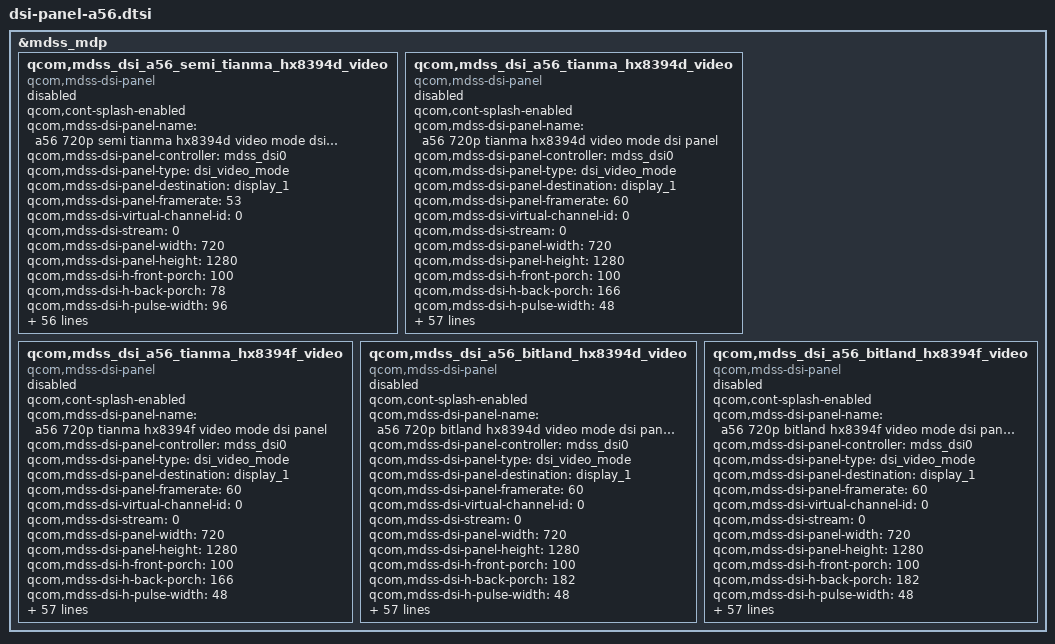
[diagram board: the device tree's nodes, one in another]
&mdss_mdp {
	qcom,mdss_dsi_a56_semi_tianma_hx8394d_video {
		compatible = "qcom,mdss-dsi-panel";
		status = "disable";
		qcom,cont-splash-enabled;
		qcom,mdss-dsi-panel-name = "a56 720p semi tianma hx8394d video mode dsi panel";
		qcom,mdss-dsi-panel-controller = <&mdss_dsi0>;
		qcom,mdss-dsi-panel-type = "dsi_video_mode";
		qcom,mdss-dsi-panel-destination = "display_1";
		qcom,mdss-dsi-panel-framerate = <53>;
		qcom,mdss-dsi-virtual-channel-id = <0>;
		qcom,mdss-dsi-stream = <0>;
		qcom,mdss-dsi-panel-width = <720>;
		qcom,mdss-dsi-panel-height = <1280>;
		qcom,mdss-dsi-h-front-porch = <100>;
		qcom,mdss-dsi-h-back-porch = <78>;
		qcom,mdss-dsi-h-pulse-width = <96>;
		qcom,mdss-dsi-h-sync-skew = <0>;
		qcom,mdss-dsi-v-back-porch = <16>;
		qcom,mdss-dsi-v-front-porch = <9>;
		qcom,mdss-dsi-v-pulse-width = <2>;
		qcom,mdss-dsi-h-left-border = <0>;
		qcom,mdss-dsi-h-right-border = <0>;
		qcom,mdss-dsi-v-top-border = <0>;
		qcom,mdss-dsi-v-bottom-border = <0>;
		qcom,mdss-dsi-bpp = <24>;
		qcom,mdss-dsi-color-order = "rgb_swap_rgb";
		qcom,mdss-dsi-underflow-color = <0xff>;
		qcom,mdss-dsi-border-color = <0>;
		qcom,mdss-dsi-on-command = [
			 39 01 00 00 00 00 04 B9 FF 83 94 /* Set EXTC */
			 39 01 00 00 00 00 03 BA 72 83 /* Set MIPI: 0x72=3Lane, 0x73=4lane */
			 39 01 00 00 00 00 10 B1 6C 0F 0F 35 04 11 F1 80 DE D4 23 80 C0 D2 18 /* Set Power */
			 39 01 00 00 00 00 0C B2 00 64 0E 0D 32 23 08 08 1C 4D 00 /* Set Display: column inversion */
			 15 01 00 00 00 00 02 BC 07 /* set VDDD: 1.7V */
			 39 01 00 00 00 00 0D B4 00 FF 03 5A 03 5A 03 5A 01 6A 01 6A  /* Set CYC(panel driving timing): column inversion */
			 39 01 00 00 00 00 26 D3 00 07 00 00 00 10 00 32 10 05 00 05 32 10 00 00 00 32 10 00 00 00 36 03 09 09 37 00 00 37 00 00 00 00 0A 00 01 /* Set GIP option 0: column inversion */
			 39 01 00 00 00 00 2D D5 02 03 00 01 06 07 04 05 20 21 22 23 18 18 18 18 18 18 18 18 18 18 18 18 18 18 18 18 18 18 18 18 18 18 18 18 18 18 24 25 18 18 19 19 /* Set GIP option 1 */
			 39 01 00 00 00 00 2D D6 05 04 07 06 01 00 03 02 23 22 21 20 18 18 18 18 18 18 18 18 18 18 18 18 18 18 18 18 18 18 18 18 18 18 18 18 18 18 25 24 19 19 18 18 /* Set GIP option 2 */
			 39 01 00 00 00 00 2B E0 00 11 16 2F 35 3F 25 3E 08 0B 0D 17 0E 12 14 13 14 07 10 11 18 00 10 17 30 35 3F 24 3E 07 0C 0D 19 0F 12 15 12 14 06 10 10 16 /* Set Gamma */
			 15 01 00 00 00 00 02 BD 00
			 39 01 00 00 00 00 2C C1 01 00 08 0E 14 1D 25 2E 36 3F 47 4F 58 60 68 70 79 81 89 91 9A A1 A8 B1 B8 C0 C9 D0 D8 E0 E8 EF F7 FF 03 B2 98 98 29 72 0F 0A C0
			 15 01 00 00 00 00 02 BD 01
			 39 01 00 00 00 00 2B C1 00 08 0D 14 1D 26 2E 37 40 48 50 59 61 69 71 7A 82 8A 93 9B A2 AA B2 B9 C2 CB D2 DA E1 E9 F0 F7 FE 0F 88 08 AD 73 DF 0D 4A 00
			 15 01 00 00 00 00 02 BD 02
			 39 01 00 00 00 00 2B C1 00 04 08 12 1B 24 2C 33 3C 44 4C 54 5C 64 6B 73 7B 83 8B 93 9B A2 A9 B0 B8 BF C7 CE D6 DC E3 E9 EE 08 03 E6 CF F6 4B 22 20 00
			 15 01 00 00 00 00 02 CC 09
			 39 01 00 00 00 00 03 C0 30 14
			 39 01 00 00 00 00 05 C7 00 C0 40 C0
			 15 01 00 00 00 00 02 51 FF
			 39 01 00 00 00 00 08 C9 1F 00 14 1E 81 1E 00
			 15 01 00 00 00 00 02 55 11  /* Set CABC mode */
			 15 01 00 00 00 00 02 5E 00  /* Set CABC minimum brightness */
			 39 01 00 00 00 00 0A CA 2D 26 25 23 22 22 21 20 20
			 39 01 00 00 00 00 23 CE 00 00 00 00 00 00 00 00 00 00 00 00 00 00 00 00 00 00 00 00 00 00 00 00 00 00 00 00 00 00 00 00 00 00
			 15 01 00 00 00 00 02 53 24 /* Set CTRL display PWM out */
			 39 01 00 00 10 00 03 E4 05 00  /* SET CE MODE */
			 39 01 00 00 00 00 20 E5 00 00 07 05 06 00 00 00 00 00 00 01 01 01 01 02 F6 08 00 08 06 05 04 06 04 04 06 06 05 03 02 /* SET CE */
			 39 01 00 00 05 00 14 E6 00 08 00 05 05 3F 20 7F 20 7F 20 10 10 10 20 20 20 00 00 /* SET CE SEL */
			 15 01 00 00 78 00 02 11 00 /* Sleep Out */
		];
		qcom,mdss-dsi-off-command = [
			05 01 00 00 0A 00 02 28 00 /* Display Off */
			05 01 00 00 28 00 02 10 00 /* Sleep In */
		];
		qcom,mdss-dsi-on-command-state = "dsi_lp_mode";
		qcom,mdss-dsi-off-command-state = "dsi_hs_mode";
		qcom,mdss-dsi-h-sync-pulse = <0>;
		qcom,mdss-dsi-traffic-mode = "non_burst_sync_event";
		qcom,mdss-dsi-bllp-eof-power-mode;
		qcom,mdss-dsi-lane-map = "lane_map_0123";
		qcom,mdss-dsi-bllp-power-mode;
		qcom,mdss-dsi-lane-0-state;
		qcom,mdss-dsi-lane-1-state;
		qcom,mdss-dsi-lane-2-state;
		qcom,mdss-dsi-panel-timings = [38 2F 25 00 43 3D 2A 31 3C 03 04 00];
		qcom,mdss-dsi-t-clk-post = <0x1F>;
		qcom,mdss-dsi-t-clk-pre = <0x39>;
		qcom,mdss-dsi-bl-min-level = <30>;
		qcom,mdss-dsi-bl-max-level = <255>;
		qcom,mdss-dsi-dma-trigger = "trigger_sw";
		qcom,mdss-dsi-mdp-trigger = "none";
		qcom,mdss-dsi-bl-pmic-control-type = "bl_ctrl_i2c";
		qcom,display-on-cmds = [05 01 00 00 0A 00 02 29 00]; /* LCD Display on */
		htc,cabc-off-cmds = [15 01 00 00 05 00 02 55 00];
		htc,cabc-ui-cmds = [
			15 01 00 00 05 00 02 55 01
			15 01 00 00 05 00 02 5E 00
			39 01 00 00 00 00 0A CA 40 30 2F 2E 2D 26 23 21 20
			39 01 00 00 00 00 23 CE 00 00 00 10 10 10 10 20 20 20 20 20 20 20 30 30 30 30 30 30 30 30 30 30 30 30 30 30 30 30 30 30 30 00
		];
		htc,cabc-video-cmds = [
			15 01 00 00 05 00 02 55 01
			15 01 00 00 05 00 02 5E 00
			39 01 00 00 00 00 0A CA 40 2E 2A 23 22 21 20 20 20
			39 01 00 00 00 00 23 CE 00 00 00 00 00 00 00 00 00 00 00 00 00 00 00 00 00 00 00 00 00 00 00 00 00 00 00 00 00 00 00 00 00 00
		];
		htc,dimming-on-cmds = [15 01 00 00 00 00 02 53 2C];
		qcom,mdss-dsi-default-command-state = "dsi_hs_mode";
		qcom,mdss-pan-physical-width-dimension = <68>;
		qcom,mdss-pan-physical-height-dimension = <121>;
		qcom,mdss-dsi-lp11-init;
		htc,brt-bl-table = <30 8>, <142 115>, <255 255>;
		htc,mdss-camera-blk = <215>;
		htc,color-temperature;
		htc,panel-id = <1>;
	};
	qcom,mdss_dsi_a56_tianma_hx8394d_video {
		compatible = "qcom,mdss-dsi-panel";
		status = "disable";
		qcom,cont-splash-enabled;
		qcom,mdss-dsi-panel-name = "a56 720p tianma hx8394d video mode dsi panel";
		qcom,mdss-dsi-panel-controller = <&mdss_dsi0>;
		qcom,mdss-dsi-panel-type = "dsi_video_mode";
		qcom,mdss-dsi-panel-destination = "display_1";
		qcom,mdss-dsi-panel-framerate = <60>;
		qcom,mdss-dsi-virtual-channel-id = <0>;
		qcom,mdss-dsi-stream = <0>;
		qcom,mdss-dsi-panel-width = <720>;
		qcom,mdss-dsi-panel-height = <1280>;
		qcom,mdss-dsi-h-front-porch = <100>;
		qcom,mdss-dsi-h-back-porch = <166>;
		qcom,mdss-dsi-h-pulse-width = <48>;
		qcom,mdss-dsi-h-sync-skew = <0>;
		qcom,mdss-dsi-v-front-porch = <16>;
		qcom,mdss-dsi-v-back-porch = <12>;
		qcom,mdss-dsi-v-pulse-width = <4>;
		qcom,mdss-dsi-h-left-border = <0>;
		qcom,mdss-dsi-h-right-border = <0>;
		qcom,mdss-dsi-v-top-border = <0>;
		qcom,mdss-dsi-v-bottom-border = <0>;
		qcom,mdss-dsi-bpp = <24>;
		qcom,mdss-dsi-color-order = "rgb_swap_rgb";
		qcom,mdss-dsi-underflow-color = <0xff>;
		qcom,mdss-dsi-border-color = <0>;
		qcom,mdss-dsi-on-command = [
			39 01 00 00 00 00 04 B9 FF 83 94 /* Set EXTC */
			39 01 00 00 00 00 03 BA 73 83 /* Set MIPI 6 */
			39 01 00 00 00 00 10 B1 6C 0F 0F 35 04 11 F1 80 DE D4 23 80 C0 D2 18 /* Set Power */
			39 01 00 00 00 00 0C B2 00 64 0E 0D 32 23 08 08 1C 4D 00 /* Set Display: column inversion */
			15 01 00 00 00 00 02 BC 07 /* set VDDD */
			39 01 00 00 00 00 0D B4 00 FF 03 5A 03 5A 03 5A 01 6A 01 6A /* Set CYC(panel driving timing): column inversion */
			39 01 00 00 00 00 21 D3 00 07 00 00 00 10 00 32 10 05 00 05 32 10 00 00 00 32 10 00 00 00 36 03 09 09 37 00 00 37 0E 08 /* Set GIP option 0: column inversion */
			39 01 00 00 00 00 2D D5 24 25 18 18 18 18 19 19 02 03 00 01 18 18 18 18 18 18 18 18 18 18 18 18 18 18 06 07 18 18 18 18 18 18 18 18 18 18 04 05 20 21 22 23 /* Set GIP option 1 */
			39 01 00 00 00 00 2D D6 25 24 18 18 19 19 18 18 05 04 07 06 18 18 18 18 18 18 58 58 18 18 18 18 18 18 01 00 18 18 18 18 18 18 18 18 18 18 03 02 23 22 21 20 /* Set GIP option 2 */
			39 01 00 00 00 00 2B E0 00 11 16 2F 35 3F 25 3E 08 0B 0D 17 0E 12 14 13 14 07 10 11 18 00 10 17 30 35 3F 24 3E 07 0C 0D 19 0F 12 15 12 14 06 10 10 16 /* Set Gamma */
			15 01 00 00 00 00 02 BD 00
			39 01 00 00 00 00 2C C1 01 00 08 10 18 20 27 2F 37 3F 47 4F 56 5E 66 6E 76 7D 85 8D 96 9E A5 AD B5 BD C5 CE D6 DE E7 EF F7 FF 00 24 97 D0 FE BA 63 87 C0
			15 01 00 00 00 00 02 BD 01
			39 01 00 00 00 00 2B C1 00 07 0F 16 1E 25 2C 33 3B 43 4A 52 59 60 68 6F 76 7D 85 8D 95 9C A3 AA B2 B9 C0 C8 D0 D8 DF E7 EF 22 2D ED B1 B9 3F 5B AE 40
			15 01 00 00 00 00 02 BD 02
			39 01 00 00 00 00 2B C1 00 08 0F 17 1F 27 2F 37 40 47 4F 57 5F 67 6E 76 7E 86 8E 97 9F A6 AE B6 BD C6 CE D7 DE E5 ED F4 FB 0F F9 3E 4F AE 69 C4 36 40
			15 01 00 00 00 00 02 CC 09 /* Set Panel */
			39 01 00 00 00 00 03 C0 30 14
			39 01 00 00 00 00 05 C7 00 C0 40 C0 /* Set TCON Option */
			15 01 00 00 00 00 02 51 FF
			39 01 00 00 00 00 08 C9 1F 00 14 1E 81 06 00
			15 01 00 00 05 00 02 55 01
			15 01 00 00 00 00 02 5E 00
			39 01 00 00 00 00 0A CA 2D 27 26 25 24 21 20 20 20
			39 01 00 00 00 00 21 CE 40 40 40 40 40 40 40 40 3C 44 43 43 00 00 00 00 00 00 00 00 00 00 00 00 00 00 00 00 00 00 00 00
			39 01 00 00 0A 00 03 E4 C3 00
			39 01 00 00 00 00 2C E5 00 08 0E 0A 09 00 20 20 20 10 00 00 00 00 00 00 80 0A 20 08 09 0A 0E 0B 0B 0A 0A 09 08 05 03 00 00 00 00 00 00 00 00 00 00 00 00
			39 01 00 00 00 00 12 E6 00 00 00 05 05 1C 18 1C 20 20 20 16 12 16 1C 20 20
			15 01 00 00 78 00 02 11 00 /* Sleep Out */
		];
		qcom,mdss-dsi-off-command = [
			05 01 00 00 0A 00 02 28 00 /* Display Off */
			05 01 00 00 28 00 02 10 00 /* Sleep In */
		];
		qcom,mdss-dsi-on-command-state = "dsi_lp_mode";
		qcom,mdss-dsi-off-command-state = "dsi_hs_mode";
		qcom,mdss-dsi-h-sync-pulse = <0>;
		qcom,mdss-dsi-traffic-mode = "non_burst_sync_event";
		qcom,mdss-dsi-bllp-eof-power-mode;
		qcom,mdss-dsi-lane-map = "lane_map_0123";
		qcom,mdss-dsi-bllp-power-mode;
		qcom,mdss-dsi-lane-0-state;
		qcom,mdss-dsi-lane-1-state;
		qcom,mdss-dsi-lane-2-state;
		qcom,mdss-dsi-lane-3-state;
		qcom,mdss-dsi-panel-timings = [38 2F 25 00 43 3D 2A 31 3C 03 04 00];
		qcom,mdss-dsi-t-clk-post = <0x1F>;
		qcom,mdss-dsi-t-clk-pre = <0x39>;
		qcom,mdss-dsi-bl-min-level = <30>;
		qcom,mdss-dsi-bl-max-level = <255>;
		qcom,mdss-dsi-dma-trigger = "trigger_sw";
		qcom,mdss-dsi-mdp-trigger = "none";
		qcom,mdss-dsi-bl-pmic-control-type = "bl_ctrl_i2c";
		qcom,display-on-cmds = [
			05 01 00 00 14 00 02 29 00
			15 01 00 00 00 00 02 53 24
		]; /* LCD Display on */
		htc,cabc-off-cmds = [15 01 00 00 05 00 02 55 00];
		htc,cabc-ui-cmds = [
			15 01 00 00 05 00 02 55 01
			15 01 00 00 05 00 02 5E 00
			39 01 00 00 00 00 0A CA 2D 27 26 25 24 21 20 20 20
			39 01 00 00 00 00 21 CE 40 40 40 40 40 40 40 40 3C 44 43 43 00 00 00 00 00 00 00 00 00 00 00 00 00 00 00 00 00 00 00 00 
		];
		htc,cabc-video-cmds = [
			15 01 00 00 05 00 02 55 01
			15 01 00 00 05 00 02 5E 00
			39 01 00 00 00 00 0A CA 40 3C 38 34 33 32 2C 21 20
			39 01 00 00 00 00 23 CE 40 40 40 40 40 40 40 40 40 44 47 4A 4C 50 50 53 55 58 5A 5C 5E 60 62 64 66 68 6A 6C 6E 6F 71 73 D0 01
		];
		htc,dimming-on-cmds = [15 01 00 00 00 00 02 53 2C];
		qcom,mdss-dsi-default-command-state = "dsi_hs_mode";
		qcom,mdss-pan-physical-width-dimension = <68>;
		qcom,mdss-pan-physical-height-dimension = <121>;
		qcom,mdss-dsi-lp11-init;
		htc,brt-bl-table = <30 8>, <142 115>, <255 255>;
		htc,mdss-camera-blk = <215>;
		htc,color-temperature;
		htc,panel-id = <2>;
	};
	qcom,mdss_dsi_a56_tianma_hx8394f_video {
		compatible = "qcom,mdss-dsi-panel";
		status = "disable";
		qcom,cont-splash-enabled;
		qcom,mdss-dsi-panel-name = "a56 720p tianma hx8394f video mode dsi panel";
		qcom,mdss-dsi-panel-controller = <&mdss_dsi0>;
		qcom,mdss-dsi-panel-type = "dsi_video_mode";
		qcom,mdss-dsi-panel-destination = "display_1";
		qcom,mdss-dsi-panel-framerate = <60>;
		qcom,mdss-dsi-virtual-channel-id = <0>;
		qcom,mdss-dsi-stream = <0>;
		qcom,mdss-dsi-panel-width = <720>;
		qcom,mdss-dsi-panel-height = <1280>;
		qcom,mdss-dsi-h-front-porch = <100>;
		qcom,mdss-dsi-h-back-porch = <166>;
		qcom,mdss-dsi-h-pulse-width = <48>;
		qcom,mdss-dsi-h-sync-skew = <0>;
		qcom,mdss-dsi-v-front-porch = <16>;
		qcom,mdss-dsi-v-back-porch = <12>;
		qcom,mdss-dsi-v-pulse-width = <4>;
		qcom,mdss-dsi-h-left-border = <0>;
		qcom,mdss-dsi-h-right-border = <0>;
		qcom,mdss-dsi-v-top-border = <0>;
		qcom,mdss-dsi-v-bottom-border = <0>;
		qcom,mdss-dsi-bpp = <24>;
		qcom,mdss-dsi-color-order = "rgb_swap_rgb";
		qcom,mdss-dsi-underflow-color = <0xff>;
		qcom,mdss-dsi-border-color = <0>;
		qcom,mdss-dsi-on-command = [
			39 01 00 00 00 00 04 B9 FF 83 94 /* Set EXTC */
			39 01 00 00 00 00 0B B1 48 10 70 09 33 54 41 31 37 2F /* Set Power */
			39 01 00 00 00 00 07 BA 63 03 68 6B B2 C0
			39 01 00 00 00 00 07 B2 00 80 64 0E 0D 48 /* Set Display: column inversion */
			39 01 00 00 00 00 1F B4 00 70 00 70 00 70 01 01 96 35 00 1F 00 8C 00 8C 00 8C 01 05 96 3F 00 FF 81 81 81 81 08 01 /* Set CYC(panel driving timing): column inversion */
			39 01 00 00 00 00 03 B6 83 83
			39 01 00 00 00 00 22 D3 00 00 14 14 00 00 10 00 32 10 05 00 05 32 10 00 00 00 32 10 00 00 00 36 03 09 09 37 00 00 37 0E 40 /* Set GIP option 0: column inversion */
			39 01 00 00 00 00 2D D5 24 25 18 18 18 18 19 19 02 03 00 01 18 18 18 18 18 18 18 18 18 18 18 18 18 18 06 07 18 18 18 18 18 18 18 18 18 18 04 05 20 21 22 23 /* Set GIP option 1 */
			39 01 00 00 00 00 2D D6 25 24 18 18 19 19 18 18 05 04 07 06 18 18 18 18 18 18 58 58 18 18 18 18 18 18 01 00 18 18 18 18 18 18 18 18 18 18 03 02 23 22 21 20 /* Set GIP option 2 */
			39 01 00 00 00 00 3B E0 00 0C 19 22 25 29 2D 2C 5B 6D 7D 7B 86 97 9C A0 AE AD A8 B2 C0 5D 5B 5E 61 63 6B 74 7F 00 0C 19 22 25 29 2D 2C 5B 6D 7D 7B 86 97 9C A0 AE AD A8 B2 C0 5D 5B 5E 61 63 6B 74 7F /* Set Gamma */
			15 01 00 00 00 00 02 BD 00
			39 01 00 00 00 00 2C C1 01 00 08 10 18 20 27 30 38 41 48 50 57 5E 65 6D 75 7D 85 8D 94 9D A4 AD B5 BC C4 CC D6 DD E6 EE F7 FF 15 B3 75 66 53 75 AC DE C0
			15 01 00 00 00 00 02 BD 01
			39 01 00 00 00 00 2B C1 00 07 0F 17 1E 25 2D 35 3E 45 4C 53 5A 60 67 6F 76 7E 87 8E 95 9D A3 AB B3 B9 C0 C8 D0 D8 E0 E7 EF 24 BE 2F 7D E8 54 28 12 C0
			15 01 00 00 00 00 02 BD 02
			39 01 00 00 00 00 2B C1 00 08 0F 17 1F 27 30 38 41 48 50 57 5E 65 6C 74 7C 84 8B 93 9B A3 AA B3 B9 C1 C8 D0 D8 E0 E7 EE F5 0F E3 75 1F 9E 8C CB DB 80
			15 01 00 00 00 00 02 CC 0B
			39 01 00 00 00 00 03 C0 1F 31
			15 01 00 00 00 00 02 BD 01
			15 01 00 00 00 00 02 B1 60
			15 01 00 00 00 00 02 BD 00
			15 01 00 00 00 00 02 35 00
			15 01 00 00 78 00 02 11 00 /* Sleep Out */
		];
		qcom,mdss-dsi-off-command = [
			05 01 00 00 0A 00 02 28 00 /* Display Off */
			05 01 00 00 28 00 02 10 00 /* Sleep In */
		];
		qcom,mdss-dsi-on-command-state = "dsi_lp_mode";
		qcom,mdss-dsi-off-command-state = "dsi_hs_mode";
		qcom,mdss-dsi-h-sync-pulse = <0>;
		qcom,mdss-dsi-traffic-mode = "non_burst_sync_event";
		qcom,mdss-dsi-bllp-eof-power-mode;
		qcom,mdss-dsi-lane-map = "lane_map_0123";
		qcom,mdss-dsi-bllp-power-mode;
		qcom,mdss-dsi-lane-0-state;
		qcom,mdss-dsi-lane-1-state;
		qcom,mdss-dsi-lane-2-state;
		qcom,mdss-dsi-lane-3-state;
		qcom,mdss-dsi-panel-timings = [38 2F 25 00 43 3D 2A 31 3C 03 04 00];
		qcom,mdss-dsi-t-clk-post = <0x1F>;
		qcom,mdss-dsi-t-clk-pre = <0x39>;
		qcom,mdss-dsi-bl-min-level = <30>;
		qcom,mdss-dsi-bl-max-level = <255>;
		qcom,mdss-dsi-dma-trigger = "trigger_sw";
		qcom,mdss-dsi-mdp-trigger = "none";
		qcom,mdss-dsi-bl-pmic-control-type = "bl_ctrl_i2c";
		qcom,display-on-cmds = [
			05 01 00 00 14 00 02 29 00
			15 01 00 00 05 00 02 51 FF
			39 01 00 00 05 00 08 C9 13 00 14 1E B1 06 00
			15 01 00 00 05 00 02 55 01
			15 01 00 00 00 00 02 5E 00
			39 01 00 00 14 00 0A CA 2D 27 26 25 24 21 20 20 20
			39 01 00 00 14 00 1B CE 3C 44 43 43 00 00 00 00 00 00 00 00 00 00 00 00 00 00 00 00 00 00 00 00 00 00
			39 01 00 00 00 00 03 E4 00 C3
			39 01 00 00 00 00 2C E5 00 08 0E 0A 09 00 20 20 20 10 00 00 00 00 00 00 80 0A 20 08 09 0A 0E 0B 0B 0A 0A 09 08 05 03 00 00 00 00 00 00 00 00 00 00 00 00
			39 01 00 00 00 00 12 E6 00 00 00 05 05 1C 18 1C 20 20 20 16 12 16 1C 20 20
			15 01 00 00 00 00 02 53 24
		]; /* LCD Display on */
		htc,cabc-off-cmds = [15 01 00 00 05 00 02 55 00];
		htc,cabc-ui-cmds = [
			15 01 00 00 05 00 02 55 01
			15 01 00 00 05 00 02 5E 00
			39 01 00 00 00 00 0A CA 2D 27 26 25 24 21 20 20 20
			39 01 00 00 00 00 1B CE 3C 44 43 43 00 00 00 00 00 00 00 00 00 00 00 00 00 00 00 00 00 00 00 00 00 00
		];
		htc,cabc-video-cmds = [
			15 01 00 00 05 00 02 55 01
			15 01 00 00 05 00 02 5E 00
			39 01 00 00 00 00 0A CA 40 3C 30 2D 28 27 22 21 20
			39 01 00 00 00 00 1B CE 40 44 47 4B 4C 52 50 53 55 58 5A 5C 5E 60 62 64 66 68 6A 6C 6E 6F 71 73 D0 01
		];
		htc,dimming-on-cmds = [15 01 00 00 00 00 02 53 2C];
		qcom,mdss-dsi-default-command-state = "dsi_hs_mode";
		qcom,mdss-pan-physical-width-dimension = <68>;
		qcom,mdss-pan-physical-height-dimension = <121>;
		qcom,mdss-dsi-lp11-init;
		htc,brt-bl-table = <30 8>, <142 115>, <255 255>;
		htc,mdss-camera-blk = <215>;
		htc,color-temperature;
		htc,panel-id = <3>;
	};
	qcom,mdss_dsi_a56_bitland_hx8394d_video {
		compatible = "qcom,mdss-dsi-panel";
		status = "disable";
		qcom,cont-splash-enabled;
		qcom,mdss-dsi-panel-name = "a56 720p bitland hx8394d video mode dsi panel";
		qcom,mdss-dsi-panel-controller = <&mdss_dsi0>;
		qcom,mdss-dsi-panel-type = "dsi_video_mode";
		qcom,mdss-dsi-panel-destination = "display_1";
		qcom,mdss-dsi-panel-framerate = <60>;
		qcom,mdss-dsi-virtual-channel-id = <0>;
		qcom,mdss-dsi-stream = <0>;
		qcom,mdss-dsi-panel-width = <720>;
		qcom,mdss-dsi-panel-height = <1280>;
		qcom,mdss-dsi-h-front-porch = <100>;
		qcom,mdss-dsi-h-back-porch = <182>;
		qcom,mdss-dsi-h-pulse-width = <48>;
		qcom,mdss-dsi-h-sync-skew = <0>;
		qcom,mdss-dsi-v-front-porch = <5>;
		qcom,mdss-dsi-v-back-porch = <5>;
		qcom,mdss-dsi-v-pulse-width = <2>;
		qcom,mdss-dsi-h-left-border = <0>;
		qcom,mdss-dsi-h-right-border = <0>;
		qcom,mdss-dsi-v-top-border = <0>;
		qcom,mdss-dsi-v-bottom-border = <0>;
		qcom,mdss-dsi-bpp = <24>;
		qcom,mdss-dsi-color-order = "rgb_swap_rgb";
		qcom,mdss-dsi-underflow-color = <0xff>;
		qcom,mdss-dsi-border-color = <0>;
		qcom,mdss-dsi-on-command = [
			39 01 00 00 00 00 04 B9 FF 83 94 /* Set EXTC */
			39 01 00 00 00 00 03 BA 73 83 /* Set MIPI 6 */
			39 01 00 00 00 00 10 B1 6C 12 12 24 04 11 F1 80 E8 54 23 80 C0 D2 58 /* Set Power */
			39 01 00 00 00 00 0C B2 00 64 05 07 22 1C 08 08 1C 4D 00 /* Set Display: column inversion */
			39 01 00 00 00 00 0D B4 00 FF 03 5A 03 5A 03 5A 01 70 01 70 /* Set CYC(panel driving timing): column inversion */
			39 01 00 00 00 00 1F D3 00 06 00 01 01 10 10 32 10 00 00 00 32 15 04 05 04 32 15 14 05 14 37 33 04 04 37 00 00 47 /* Set GIP option 0: column inversion */
			39 01 00 00 00 00 2D D5 18 18 25 24 27 26 11 10 15 14 13 12 17 16 01 00 18 18 18 18 18 18 18 18 18 18 05 04 03 02 07 06 18 18 18 18 21 20 23 22 18 18 18 18 /* Set GIP option 1 */
			39 01 00 00 00 00 2D D6 18 18 22 23 20 21 12 13 16 17 10 11 14 15 06 07 18 18 18 18 18 18 18 18 18 18 02 03 04 05 00 01 18 18 18 18 26 27 24 25 18 18 18 18 /* Set GIP option 2 */
			15 01 00 00 00 00 02 BD 02
			39 01 00 00 00 00 0D D8 BF FF AA BF AF F0 9D FF AA BF AF F0
			15 01 00 00 00 00 02 BD 00
			39 01 00 00 00 00 2B E0 00 05 0A 2E 33 3F 1B 3E 06 0A 0C 17 0F 12 15 13 14 07 12 13 17 00 05 0A 2E 33 3F 1B 3E 06 0A 0C 17 0F 12 15 13 14 07 12 13 17 /* Set Gamma */
			15 01 00 00 00 00 02 CC 09 /* Set Panel */
			39 01 00 00 00 00 03 C0 30 14
			39 01 00 00 00 00 05 C7 00 C0 40 C0 /* Set TCON Option */
			15 01 00 00 00 00 02 BD 00
			39 01 00 00 00 00 2C C1 01 00 08 10 18 20 28 30 38 40 47 4F 57 5F 68 70 78 7F 87 8F 97 9F A8 B0 B8 C0 C8 D0 D8 E0 E8 F0 F8 FF 16 D6 6A C0 D3 CE 65 45 C0
			15 01 00 00 00 00 02 BD 01
			39 01 00 00 00 00 2B C1 00 08 0F 17 1F 26 2D 35 3D 44 4B 53 5B 62 6A 72 79 81 88 90 98 9F A7 B0 B7 BE C6 CE D6 DD E5 ED F5 0E 4E 54 24 C0 3C BE 79 80
			15 01 00 00 00 00 02 BD 02
			39 01 00 00 00 00 2B C1 00 07 0E 15 1C 23 2A 32 3A 41 48 4F 57 5E 66 6D 75 7C 83 8B 92 9A A2 AA B2 B9 C0 C7 CF D6 DD E4 EB 00 2D 01 22 28 F4 43 66 40
			15 01 00 00 78 00 02 11 00 /* Sleep Out */
		];
		qcom,mdss-dsi-off-command = [
			05 01 00 00 0A 00 02 28 00 /* Display Off */
			05 01 00 00 28 00 02 10 00 /* Sleep In */
		];
		qcom,mdss-dsi-on-command-state = "dsi_lp_mode";
		qcom,mdss-dsi-off-command-state = "dsi_hs_mode";
		qcom,mdss-dsi-h-sync-pulse = <0>;
		qcom,mdss-dsi-traffic-mode = "non_burst_sync_event";
		qcom,mdss-dsi-bllp-eof-power-mode;
		qcom,mdss-dsi-lane-map = "lane_map_0123";
		qcom,mdss-dsi-bllp-power-mode;
		qcom,mdss-dsi-lane-0-state;
		qcom,mdss-dsi-lane-1-state;
		qcom,mdss-dsi-lane-2-state;
		qcom,mdss-dsi-lane-3-state;
		qcom,mdss-dsi-panel-timings = [38 2F 25 00 43 3D 2A 31 3C 03 04 00];
		qcom,mdss-dsi-t-clk-post = <0x1F>;
		qcom,mdss-dsi-t-clk-pre = <0x39>;
		qcom,mdss-dsi-bl-min-level = <30>;
		qcom,mdss-dsi-bl-max-level = <255>;
		qcom,mdss-dsi-dma-trigger = "trigger_sw";
		qcom,mdss-dsi-mdp-trigger = "none";
		qcom,mdss-dsi-bl-pmic-control-type = "bl_ctrl_i2c";
		qcom,display-on-cmds = [
			05 01 00 00 14 00 02 29 00 /* LCD Display on */
			15 01 00 00 05 00 02 51 FF
			39 01 00 00 05 00 08 C9 1F 00 2E 1E B1 06 00 /* Set CABC control */
			15 01 00 00 05 00 02 55 01
			15 01 00 00 00 00 02 5E 00
			39 01 00 00 00 00 0A CA 2D 27 26 25 24 21 20 20 20
			39 01 00 00 00 00 23 CE 40 40 40 40 40 40 40 40 3C 44 43 43 00 00 00 00 00 00 00 00 00 00 00 00 00 00 00 00 00 00 00 00 00 00
			39 01 00 00 0A 00 03 E4 C3 00
			39 01 00 00 00 00 2C E5 00 08 0E 0A 09 00 20 20 20 10 00 00 00 00 00 00 80 0A 20 08 09 0A 0E 0B 0B 0A 0A 09 08 05 03 00 00 00 00 00 00 00 00 00 00 00 00
			39 01 00 00 05 00 12 E6 00 00 00 05 05 1C 18 1C 20 20 20 16 12 16 1C 20 20
			15 01 00 00 00 00 02 53 24
		];
		htc,cabc-off-cmds = [15 01 00 00 05 00 02 55 00];
		htc,cabc-ui-cmds = [
			15 01 00 00 05 00 02 55 01
			15 01 00 00 05 00 02 5E 00
			39 01 00 00 00 00 0A CA 2D 27 26 25 24 21 20 20 20
			39 01 00 00 00 00 21 CE 40 40 40 40 40 40 40 40 3C 44 43 43 00 00 00 00 00 00 00 00 00 00 00 00 00 00 00 00 00 00 00 00 00 00
		];
		htc,cabc-video-cmds = [
			15 01 00 00 05 00 02 55 01
			15 01 00 00 05 00 02 5E 00
			39 01 00 00 00 00 0A CA 40 3C 38 31 2D 2C 2B 21 20
			39 01 00 00 00 00 23 CE 40 40 40 40 40 40 40 40 40 43 47 4A 4C 50 50 53 55 58 5A 5C 5E 60 62 64 66 68 6A 6C 6E 6F 71 73 D0 01
		];
		htc,dimming-on-cmds = [15 01 00 00 00 00 02 53 2C];
		qcom,mdss-dsi-default-command-state = "dsi_hs_mode";
		qcom,mdss-pan-physical-width-dimension = <68>;
		qcom,mdss-pan-physical-height-dimension = <121>;
		qcom,mdss-dsi-lp11-init;
		htc,brt-bl-table = <30 7>, <142 94>, <255 255>;
		htc,mdss-camera-blk = <194>;
		htc,color-temperature;
		htc,panel-id = <4>;
	};
	qcom,mdss_dsi_a56_bitland_hx8394f_video {
		compatible = "qcom,mdss-dsi-panel";
		status = "disable";
		qcom,cont-splash-enabled;
		qcom,mdss-dsi-panel-name = "a56 720p bitland hx8394f video mode dsi panel";
		qcom,mdss-dsi-panel-controller = <&mdss_dsi0>;
		qcom,mdss-dsi-panel-type = "dsi_video_mode";
		qcom,mdss-dsi-panel-destination = "display_1";
		qcom,mdss-dsi-panel-framerate = <60>;
		qcom,mdss-dsi-virtual-channel-id = <0>;
		qcom,mdss-dsi-stream = <0>;
		qcom,mdss-dsi-panel-width = <720>;
		qcom,mdss-dsi-panel-height = <1280>;
		qcom,mdss-dsi-h-front-porch = <100>;
		qcom,mdss-dsi-h-back-porch = <182>;
		qcom,mdss-dsi-h-pulse-width = <48>;
		qcom,mdss-dsi-h-sync-skew = <0>;
		qcom,mdss-dsi-v-front-porch = <5>;
		qcom,mdss-dsi-v-back-porch = <5>;
		qcom,mdss-dsi-v-pulse-width = <2>;
		qcom,mdss-dsi-h-left-border = <0>;
		qcom,mdss-dsi-h-right-border = <0>;
		qcom,mdss-dsi-v-top-border = <0>;
		qcom,mdss-dsi-v-bottom-border = <0>;
		qcom,mdss-dsi-bpp = <24>;
		qcom,mdss-dsi-color-order = "rgb_swap_rgb";
		qcom,mdss-dsi-underflow-color = <0xff>;
		qcom,mdss-dsi-border-color = <0>;
		qcom,mdss-dsi-on-command = [
			39 01 00 00 00 00 04 B9 FF 83 94 /* Set EXTC */
			39 01 00 00 00 00 07 BA 63 03 68 6B B2 C0 /* Set MIPI 6 */
			39 01 00 00 00 00 0B B1 48 12 72 09 32 44 71 31 4D 2F /* Set Power */
			39 01 00 00 00 00 06 B2 00 80 64 05 07 /* Set Display: column inversion */
			39 01 00 00 00 00 16 B4 26 76 26 76 26 26 05 10 85 75 00 3F 26 76 26 76 26 26 05 10 86 /* Set CYC(panel driving timing): column inversion */
			39 01 00 00 00 00 22 D3 00 00 06 06 01 01 10 10 32 10 00 00 00 32 15 04 05 04 32 15 14 05 14 37 33 04 04 37 00 00 47 05 40 /* Set GIP option 0: column inversion */
			39 01 00 00 00 00 2D D5 18 18 25 24 27 26 11 10 15 14 13 12 17 16 01 00 18 18 18 18 18 18 18 18 18 18 05 04 03 02 07 06 18 18 18 18 21 20 23 22 18 18 18 18 /* Set GIP option 1 */
			39 01 00 00 00 00 2D D6 18 18 22 23 20 21 12 13 16 17 10 11 14 15 06 07 18 18 18 18 18 18 18 18 18 18 02 03 04 05 00 01 18 18 18 18 26 27 24 25 18 18 18 18 /* Set GIP option 2 */
			39 01 00 00 00 00 3B E0 00 05 0D 13 15 1A 1D 1C 3C 4F 61 62 70 86 90 95 A4 A7 A3 B1 C0 5E 5C 60 64 68 6E 7D 7F 00 05 0D 13 15 1A 1D 1C 3C 4F 61 62 70 86 90 95 A4 A7 A3 B1 C0 5E 5C 60 64 68 6E 7D 7F /* Set Gamma */
			15 01 00 00 00 00 02 CC 0B /* Set Panel */
			39 01 00 00 00 00 03 C0 1F 31
			15 01 00 00 00 00 02 D4 02 /* Set EMI enhance */
			15 01 00 00 00 00 02 BD 01 /* Set BD */
			15 01 00 00 00 00 02 B1 60 /* Set Power */
			15 01 00 00 00 00 02 BD 00
			39 01 00 00 00 00 2C C1 01 00 08 10 18 20 28 30 38 40 48 50 58 60 68 70 78 80 87 8F 97 9F A7 B0 B7 BF C8 D0 D8 E0 E8 F0 F8 FF 16 C7 A7 F0 BB F3 85 04 C0
			15 01 00 00 00 00 02 BD 01
			39 01 00 00 00 00 2B C1 00 08 0F 17 1F 26 2E 36 3E 46 4D 55 5D 65 6C 73 7B 83 8A 92 9A A1 A9 B1 B9 C0 C9 D0 D8 E0 E7 F0 F7 0E BE 8A 97 DD 7B 33 9C C0
			15 01 00 00 00 00 02 BD 02
			39 01 00 00 00 00 2B C1 00 07 0E 15 1D 24 2C 33 3B 42 49 51 59 60 67 6F 76 7E 85 8C 93 9B A2 AA B2 B9 C0 C8 CF D6 DD E4 EB 1B 21 7D 7C 85 E8 04 7F 80
			15 01 00 00 00 00 02 BD 01
			15 01 00 00 00 00 02 B1 00
			15 01 00 00 00 00 02 BD 00 /* Set BD */
			15 01 00 00 78 00 02 11 00 /* Sleep Out */
		];
		qcom,mdss-dsi-off-command = [
			05 01 00 00 0A 00 02 28 00 /* Display Off */
			05 01 00 00 28 00 02 10 00 /* Sleep In */
		];
		qcom,mdss-dsi-on-command-state = "dsi_lp_mode";
		qcom,mdss-dsi-off-command-state = "dsi_hs_mode";
		qcom,mdss-dsi-h-sync-pulse = <0>;
		qcom,mdss-dsi-traffic-mode = "non_burst_sync_event";
		qcom,mdss-dsi-bllp-eof-power-mode;
		qcom,mdss-dsi-lane-map = "lane_map_0123";
		qcom,mdss-dsi-bllp-power-mode;
		qcom,mdss-dsi-lane-0-state;
		qcom,mdss-dsi-lane-1-state;
		qcom,mdss-dsi-lane-2-state;
		qcom,mdss-dsi-lane-3-state;
		qcom,mdss-dsi-panel-timings = [38 2F 25 00 43 3D 2A 31 3C 03 04 00];
		qcom,mdss-dsi-t-clk-post = <0x1F>;
		qcom,mdss-dsi-t-clk-pre = <0x39>;
		qcom,mdss-dsi-bl-min-level = <30>;
		qcom,mdss-dsi-bl-max-level = <255>;
		qcom,mdss-dsi-dma-trigger = "trigger_sw";
		qcom,mdss-dsi-mdp-trigger = "none";
		qcom,mdss-dsi-bl-pmic-control-type = "bl_ctrl_i2c";
		qcom,display-on-cmds = [
			39 01 00 00 00 00 0D B2 00 80 64 05 07 2F 00 00 00 00 C0 18
			05 01 00 00 14 00 02 29 00 /* LCD Display on */
			15 01 00 00 05 00 02 51 FF
			39 01 00 00 05 00 08 C9 13 00 14 1E B1 06 00
			15 01 00 00 05 00 02 55 01
			15 01 00 00 00 00 02 5E 00
			39 01 00 00 14 00 0A CA 2D 27 26 25 24 21 20 20 20
			39 01 00 00 14 00 1B CE 3C 44 43 43 00 00 00 00 00 00 00 00 00 00 00 00 00 00 00 00 00 00 00 00 00 00
			39 01 00 00 00 00 03 E4 00 C3
			39 01 00 00 00 00 2C E5 00 08 0E 0A 09 00 20 20 20 10 00 00 00 00 00 00 80 0A 20 08 09 0A 0E 0B 0B 0A 0A 09 08 05 03 00 00 00 00 00 00 00 00 00 00 00 00
			39 01 00 00 00 00 12 E6 00 00 00 05 05 1C 18 1C 20 20 20 16 12 16 1C 20 20
			15 01 00 00 00 00 02 53 24
		];
		htc,cabc-off-cmds = [15 01 00 00 05 00 02 55 00];
		htc,cabc-ui-cmds = [
			15 01 00 00 05 00 02 55 01
			15 01 00 00 05 00 02 5E 00
			39 01 00 00 00 00 0A CA 2D 27 26 25 24 21 20 20 20
			39 01 00 00 00 00 1B CE 3C 44 43 43 00 00 00 00 00 00 00 00 00 00 00 00 00 00 00 00 00 00 00 00 00 00
		];
		htc,cabc-video-cmds = [
			15 01 00 00 05 00 02 55 01
			15 01 00 00 05 00 02 5E 00
			39 01 00 00 00 00 0A CA 40 3C 30 2B 24 23 22 21 20
			39 01 00 00 00 00 1B CE 40 43 46 4B 4C 52 50 53 55 58 5A 5C 5E 60 62 64 66 68 6A 6C 6E 6F 71 73 D0 01
		];
		htc,dimming-on-cmds = [15 01 00 00 00 00 02 53 2C];
		qcom,mdss-dsi-default-command-state = "dsi_hs_mode";
		qcom,mdss-pan-physical-width-dimension = <68>;
		qcom,mdss-pan-physical-height-dimension = <121>;
		qcom,mdss-dsi-lp11-init;
		htc,brt-bl-table = <30 7>, <142 94>, <255 255>;
		htc,mdss-camera-blk = <194>;
		htc,color-temperature;
		htc,panel-id = <5>;
	};
};
